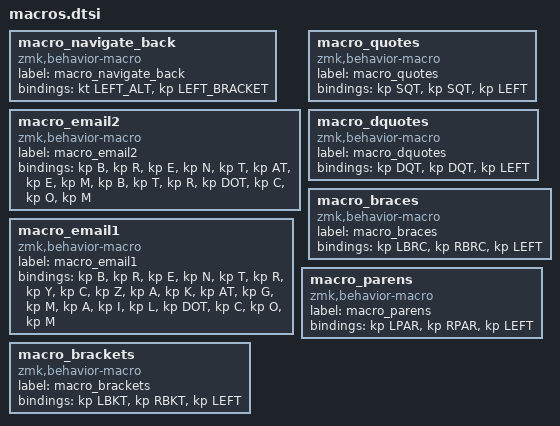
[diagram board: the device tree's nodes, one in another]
macro_navigate_back: macro_navigate_back{
compatible = "zmk,behavior-macro";
label = "macro_navigate_back";
#binding-cells = <0>;
bindings = <&kt LEFT_ALT>, <&kp LEFT_BRACKET>;
};
macro_email2: macro_email2{
compatible = "zmk,behavior-macro";
label = "macro_email2";
#binding-cells = <0>;
bindings = <&kp B>, <&kp R>, <&kp E>, <&kp N>, <&kp T>, <&kp AT>, <&kp E>, <&kp M>, <&kp B>, <&kp T>, <&kp R>, <&kp DOT>, <&kp C>, <&kp O>, <&kp M>;
};
macro_email1: macro_email1{
compatible = "zmk,behavior-macro";
label = "macro_email1";
#binding-cells = <0>;
bindings = <&kp B>, <&kp R>, <&kp E>, <&kp N>, <&kp T>, <&kp R>, <&kp Y>, <&kp C>, <&kp Z>, <&kp A>, <&kp K>, <&kp AT>, <&kp G>, <&kp M>, <&kp A>, <&kp I>, <&kp L>, <&kp DOT>, <&kp C>, <&kp O>, <&kp M>;
};
macro_quotes: macro_quotes{
compatible = "zmk,behavior-macro";
label = "macro_quotes";
#binding-cells = <0>;
bindings = <&kp SQT>, <&kp SQT>, <&kp LEFT>;
};
macro_dquotes: macro_dquotes{
compatible = "zmk,behavior-macro";
label = "macro_dquotes";
#binding-cells = <0>;
bindings = <&kp DQT>, <&kp DQT>, <&kp LEFT>;
};
macro_braces: macro_braces{
compatible = "zmk,behavior-macro";
label = "macro_braces";
#binding-cells = <0>;
bindings = <&kp LBRC>, <&kp RBRC>, <&kp LEFT>;
};
macro_parens: macro_parens{
compatible = "zmk,behavior-macro";
label = "macro_parens";
#binding-cells = <0>;
bindings = <&kp LPAR>, <&kp RPAR>, <&kp LEFT>;
};
macro_brackets: macro_brackets{
compatible = "zmk,behavior-macro";
label = "macro_brackets";
#binding-cells = <0>;
bindings = <&kp LBKT>, <&kp RBKT>, <&kp LEFT>;
};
